# AC33Mx384A register map
Vendor: ABOV Semiconductor Co., Ltd.; File version: 0.1
CPU: CM3 r1p0, little endian, no MPU, no FPU, 3 interrupt priority bits
Registers are 32-bit, read-write, reset 0x0 unless marked. A register's access mark holds for its fields unless they carry their own. Offsets are from the block's base; [hi:lo] are bit positions; {n}, {i} and the like mark numbered series; 'fields as' and 'values as' point back to an identical list.

## IC0 — IIC Interface
Base 0x4000A000
Same registers: IC1 0x4000A100
0x00 DR — IIC Data Register
  [7:0] DR — Data
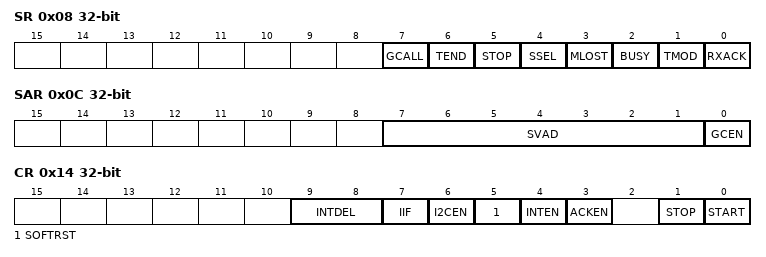
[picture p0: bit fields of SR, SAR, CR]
0x08 SR — Status register
  [7] GCALL — General call flag
  [6] TEND — 1 byte transmission complete flag
  [5] STOP — Stop Flag
  [4] SSEL — slave flag
  [3] MLOST — Mastership lost flag
  [2] BUSY — busy flag
  [1] TMOD — Transmit/reciever mode flag
  [0] RXACK — RX ack flag
0x0C SAR — IIC Slave Address Register
  [7:1] SVAD — 7 bits slave address
  [0] GCEN — general call enable bit
0x14 CR — IIC Control Register
  [9:8] INTDEL — Interval delay value between address and data transfer
  [7] IIF — Interrupt flag bit
  [6] I2CEN — I2C enable bit
  [5] SOFTRST — Soft reset enable bit
  [4] INTEN — Interrupt enable bit
  [3] ACKEN — ACK enabit bit in receiver mode
  [1] STOP — Stop enable bit
  [0] START — transmission start bit in master mode
0x18 SCLL reset 0xFFFF — IIC SCL LOW duration Register
  [15:0] SCLL — SCL Low duration value
0x1C SCLH reset 0xFFFF — IIC SCL HIGH duration Register
  [15:0] SCLH — SCL High duration value
0x20 SDH (reset mask 0x3FFF) — SDA Hold Register
  [14:0] SDH — SDA Hold time

## MP0 — MOTOR PULSE-WIDTH-MODULATOR
Base 0x40004000
Same registers: MP1 0x40005000
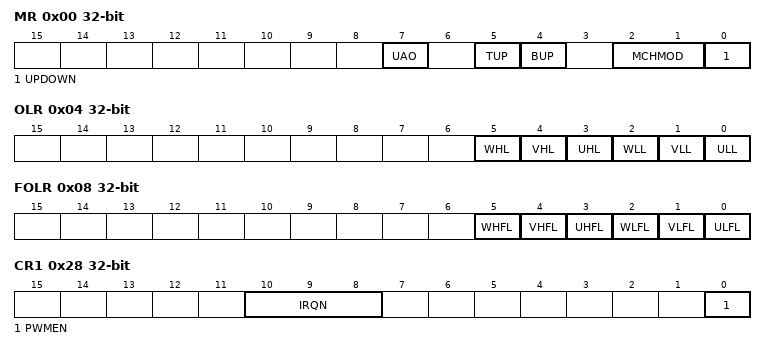
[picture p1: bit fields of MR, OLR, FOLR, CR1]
0x00 MR — MPWM Mode Register
  [7] UAO
  [5] TUP
  [4] BUP
  [2:1] MCHMOD
  [0] UPDOWN — PWM counter mode
0x04 OLR — MPWM Port Mode Register
  [5] WHL, [4] VHL, [3] UHL, [2] WLL, [1] VLL, [0] ULL
0x08 FOLR — MPWM Force Output Level Register
  [5] WHFL, [4] VHFL, [3] UHFL, [2] WLFL, [1] VLFL, [0] ULFL
0x0C PRD — MPWM Period Register
  [15:0] PERIOD — PWM period
0x10 DUH — MPWM Duty UH Register
  [15:0] DUTY — duty of UH output
0x14 DVH — MPWM Duty VH Register
  [15:0] DUTY — duty of VH data
0x18 DWH — MPWM Duty WH Register
  [15:0] DUTY — duty of WH output
0x1C DUL — MPWM Duty UL Register
  [15:0] DUTY — duty of UL output
0x20 DVL — MPWM Duty VL Register
  [15:0] DUTY — duty of VL output
0x24 DWL — MPWM Duty WL Register
  [15:0] DUTY — duty of WL output
0x28 CR1 — MPWM Control Register 1
  [10:8] IRQN — IRQ intervel Number
  [0] PWMEN
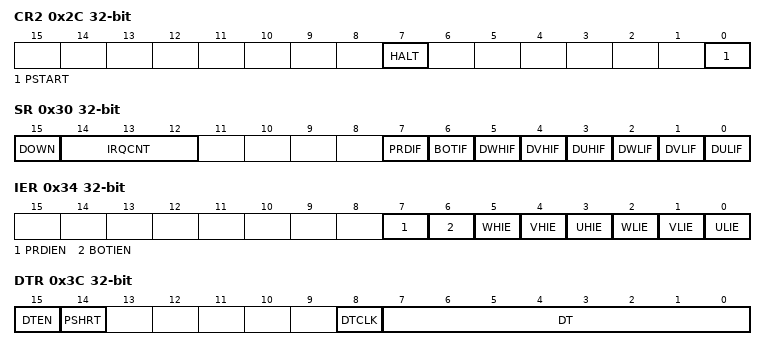
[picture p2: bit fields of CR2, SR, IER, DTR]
0x2C CR2 — MPWM Control Register 2
  [7] HALT
  [0] PSTART — PWM start
0x30 SR — MPWM Status Register
  [15] DOWN — PWM count up/down
  [14:12] IRQCNT — Interrupt count number of period match
  [7] PRDIF — PWM period interrupt flag
  [6] BOTIF — PWM bottom interrupt flag
  [5] DWHIF — PWM duty WH interrupt flag
  [4] DVHIF — PWM duty VH interrupt flag
  [3] DUHIF — PWM duty UH interrupt flag
  [2] DWLIF — PWM duty WL interrupt flag
  [1] DVLIF — PWM duty VL interrupt flag
  [0] DULIF — PWM duty UL interrupt flag
0x34 IER — MPWM Interrupt Enable Register
  [7] PRDIEN — Period interrupt enable
  [6] BOTIEN — bottom interrupt enable
  [5] WHIE — WH Duty or ATR6 Match Interrupt enable
  [4] VHIE — VH Duty or ATR5 Match Interrupt enable
  [3] UHIE — UH Duty or ATR4 Match Interrupt enable
  [2] WLIE — WL Duty or ATR3 Match Interrupt enable
  [1] VLIE — VL Duty or ATR2 Match Interrupt enable
  [0] ULIE — UL Duty or ATR1 Match Interrupt enable
0x38 CNT — MPWM Counter Register
  [15:0] CNT — pwm counter value
0x3C DTR — MPWM Dead Time Register
  [15] DTEN — dead time Enable
  [14] PSHRT
  [8] DTCLK — dead time clk select
  [7:0] DT — dead time value
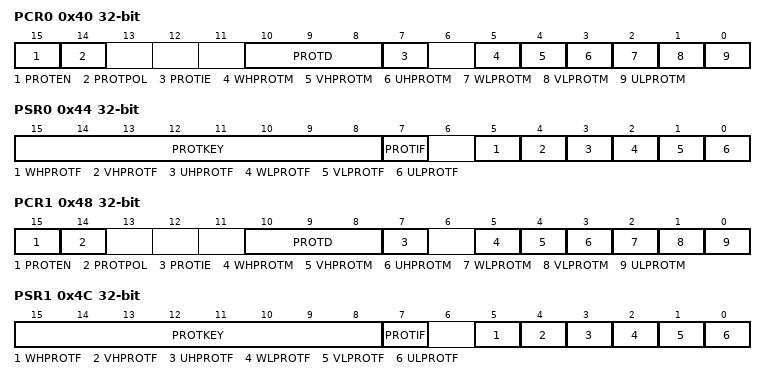
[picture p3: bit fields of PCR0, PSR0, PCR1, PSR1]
0x40 PCR0 — MPWM Protection control Register 0
  [15] PROTEN, [14] PROTPOL, [10:8] PROTD, [7] PROTIE, [5] WHPROTM, [4] VHPROTM, [3] UHPROTM, [2] WLPROTM, [1] VLPROTM, [0] ULPROTM
0x44 PSR0 — MPWM Protection Status Register 0
  [15:8] PROTKEY — Protection Clear Access Key
  [7] PROTIF — Protection Interrupt status
  [5] WHPROTF — Activate W-phase H-side protection flag
  [4] VHPROTF — Activate V-phase H-side protection flag
  [3] UHPROTF — Activate U-phase H-side protection flag
  [2] WLPROTF — Activate W-phase L-side protection flag
  [1] VLPROTF — Activate V-phase L-side protection flag
  [0] ULPROTF — Activate U-phase L-side protection flag
0x48 PCR1 — MPWM Protection control Register 1
  fields as PCR0
0x4C PSR1 — MPWM Protection Status Register 1
  fields as PSR0
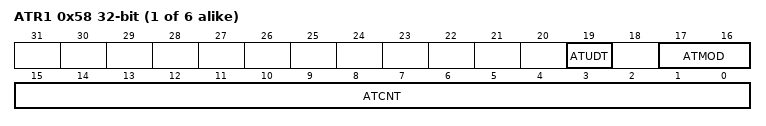
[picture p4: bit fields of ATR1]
{0x54+4i} ATR{i} (i=1..6) — MPWMn ADC Trigger Counter {i} Register
  [19] ATUDT — Trigger register update mode
  [17:16] ATMOD — ADC Trigger mode register
  [15:0] ATCNT — ADC Trigger counter

## AD0 — 12-BIT A/D CONVERTER
Base 0x4000B000
Same registers: AD1 0x4000B100
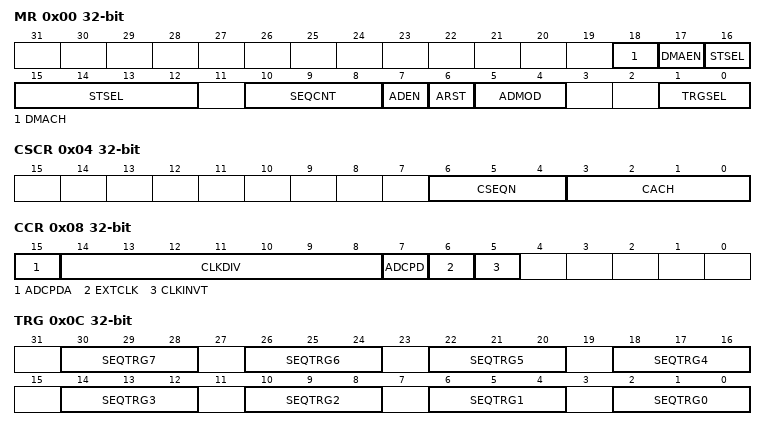
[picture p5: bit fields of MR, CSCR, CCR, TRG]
0x00 MR — ADCn Mode Register
  [18] DMACH — DMA channel option
  [17] DMAEN — DMA enable
  [16:12] STSEL
  [10:8] SEQCNT
  [7] ADEN — ADC Enable
  [6] ARST
  [5:4] ADMOD — ADC convert mode
  [1:0] TRGSEL
0x04 CSCR — Current Sequence/Channel Register
  [6:4] CSEQN
  [3:0] CACH — Current Active Channel
0x08 CCR — Clock Control Register
  [15] ADCPDA — ADC R-ADC disable to save power
  [14:8] CLKDIV — ADC clock divider
  [7] ADCPD — ADC Power down
  [6] EXTCLK — ADCuse external clock
  [5] CLKINVT — divided clock inversion
0x0C TRG — ADC Trigger Selection Register
  [4n+2:4n] SEQTRG{n} (n=3..7) — {n+1}th Sequence Trigger Source
  [10:8] SEQTRG2 — 3rd Sequence Trigger Source
  [6:4] SEQTRG1 — 2nd Sequence Trigger Source
  [2:0] SEQTRG0 — 1st Sequence Trigger Source
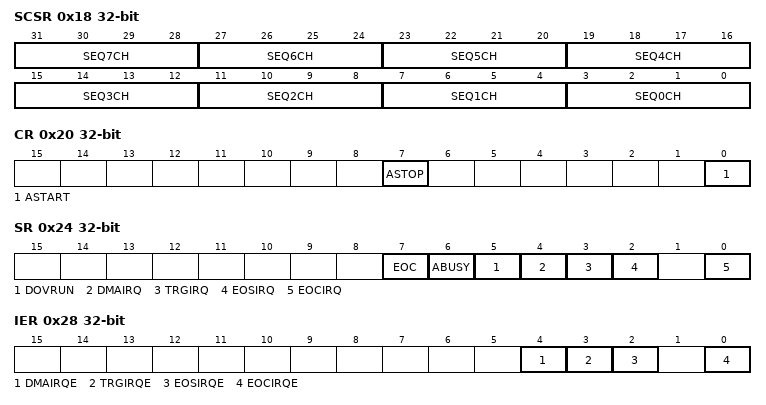
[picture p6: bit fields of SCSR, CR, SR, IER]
0x18 SCSR — ADC Sequence Channel Selection Register
  [4n+3:4n] SEQ{n}CH (n=3..7) — {n+1}th conversion sequence channel selection
  [11:8] SEQ2CH — 3rd conversion sequence channel selection
  [7:4] SEQ1CH — 2nd conversion sequence channel selection
  [3:0] SEQ0CH — 1st conversion sequence channel selection
0x20 CR — ADCn Control Register
  [7] ASTOP wo — ADC Stop
  [0] ASTART — ADC conversion start
0x24 SR — ADCn Status Register
  [7] EOC — ADC End Flag
  [6] ABUSY — ADC conversion busy flag
  [5] DOVRUN — DMA overrun flag
  [4] DMAIRQ — DMA received/transfer is done
  [3] TRGIRQ — ADC Trigger interrupt flag
  [2] EOSIRQ
  [0] EOCIRQ
0x28 IER — Interrupt Enable Register
  [4] DMAIRQE — DMA done interrupt enable
  [3] TRGIRQE — ADC trigger conversion interrupt enable
  [2] EOSIRQE — ADC sequence conversion interrupt enable
  [0] EOCIRQE — ADC single conversion interrupt enable
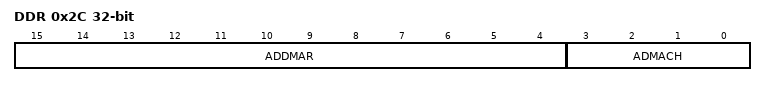
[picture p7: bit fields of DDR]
0x2C DDR — ADC DMA Data Register
  [15:4] ADDMAR — ADC conversion result data
  [3:0] ADMACH — ADC data channel indicator
{0x30+4i} DR{i} (i=0..7) — ADC Data Register {i}
  [15:4] ADCDATA — ADC conversion result data
